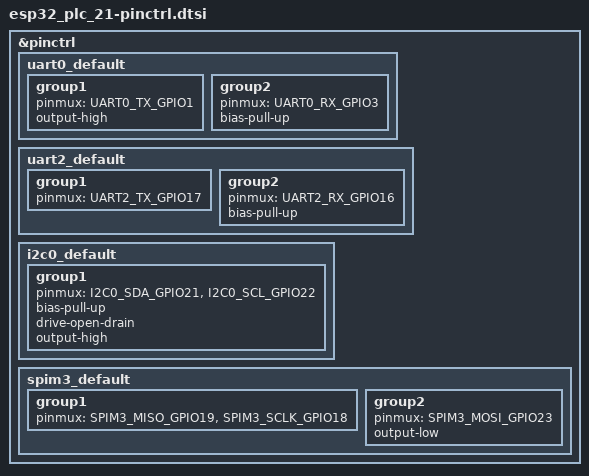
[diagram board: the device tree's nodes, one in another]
/*
 * Copyright (c) 2026 New Mexico Drip Inc.
 *
 * SPDX-License-Identifier: Apache-2.0
 */

#include <zephyr/dt-bindings/pinctrl/esp-pinctrl-common.h>
#include <dt-bindings/pinctrl/esp32-pinctrl.h>
#include <zephyr/dt-bindings/pinctrl/esp32-gpio-sigmap.h>

&pinctrl {

	/* USB-bridge console (Industrial Shields front-panel USB-C). */
	uart0_default: uart0_default {
		group1 {
			pinmux = <UART0_TX_GPIO1>;
			output-high;
		};
		group2 {
			pinmux = <UART0_RX_GPIO3>;
			bias-pull-up;
		};
	};

	/* RS-485 hard-wired transceiver on the screw terminal block.
	 * DE/RE direction control is GPIO4, driven by the UART2 driver
	 * (see &uart2 dir-gpios in the .dts).
	 */
	uart2_default: uart2_default {
		group1 {
			pinmux = <UART2_TX_GPIO17>;
		};
		group2 {
			pinmux = <UART2_RX_GPIO16>;
			bias-pull-up;
		};
	};

	/* I2C0: on-board peripheral bus.
	 * Devices: MCP23008 @ 0x21, ADS1015 @ 0x48 + 0x49,
	 *          PCA9685 @ 0x40, DS3231 RTC @ 0x68.
	 */
	i2c0_default: i2c0_default {
		group1 {
			pinmux = <I2C0_SDA_GPIO21>,
				 <I2C0_SCL_GPIO22>;
			bias-pull-up;
			drive-open-drain;
			output-high;
		};
	};

	/* SPI3 (VSPI): shared bus for W5500 Ethernet (CS=GPIO15) and SD (CS=GPIO13). */
	spim3_default: spim3_default {
		group1 {
			pinmux = <SPIM3_MISO_GPIO19>,
				 <SPIM3_SCLK_GPIO18>;
		};
		group2 {
			pinmux = <SPIM3_MOSI_GPIO23>;
			output-low;
		};
	};
};
